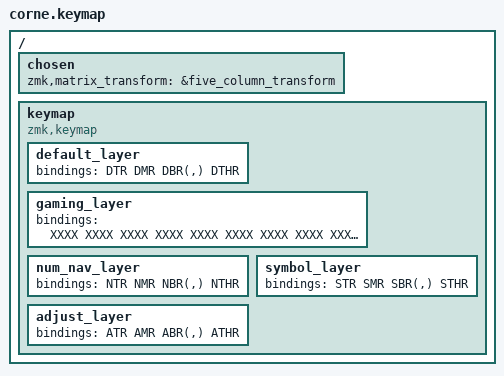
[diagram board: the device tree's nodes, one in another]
#include <behaviors.dtsi>

#include "base.keymap"

/ {
  chosen {
    zmk,matrix_transform = &five_column_transform;
  };

  keymap {
    compatible = "zmk,keymap";
    default_layer { 
      bindings = <
        DTR
        DMR
        DBR(,)
        DTHR
      >;
    };

    gaming_layer { 
      bindings = <
        XXXX XXXX XXXX XXXX XXXX  XXXX XXXX XXXX XXXX XXXX
        XXXX XXXX XXXX XXXX XXXX  XXXX XXXX XXXX XXXX XXXX
        XXXX XXXX XXXX XXXX XXXX  XXXX XXXX XXXX XXXX XXXX
                  XXXX XXXX XXXX  XXXX XXXX XXXX
      >;
    };
        
    num_nav_layer { 
      bindings = <
        NTR
        NMR
        NBR(,)
        NTHR
      >;
    };

    symbol_layer { 
      bindings = <
        STR
        SMR
        SBR(,)
        STHR
      >;
    };
        
    adjust_layer { 
      bindings = <
        ATR
        AMR
        ABR(,)
        ATHR
      >;
    };
  };
};
